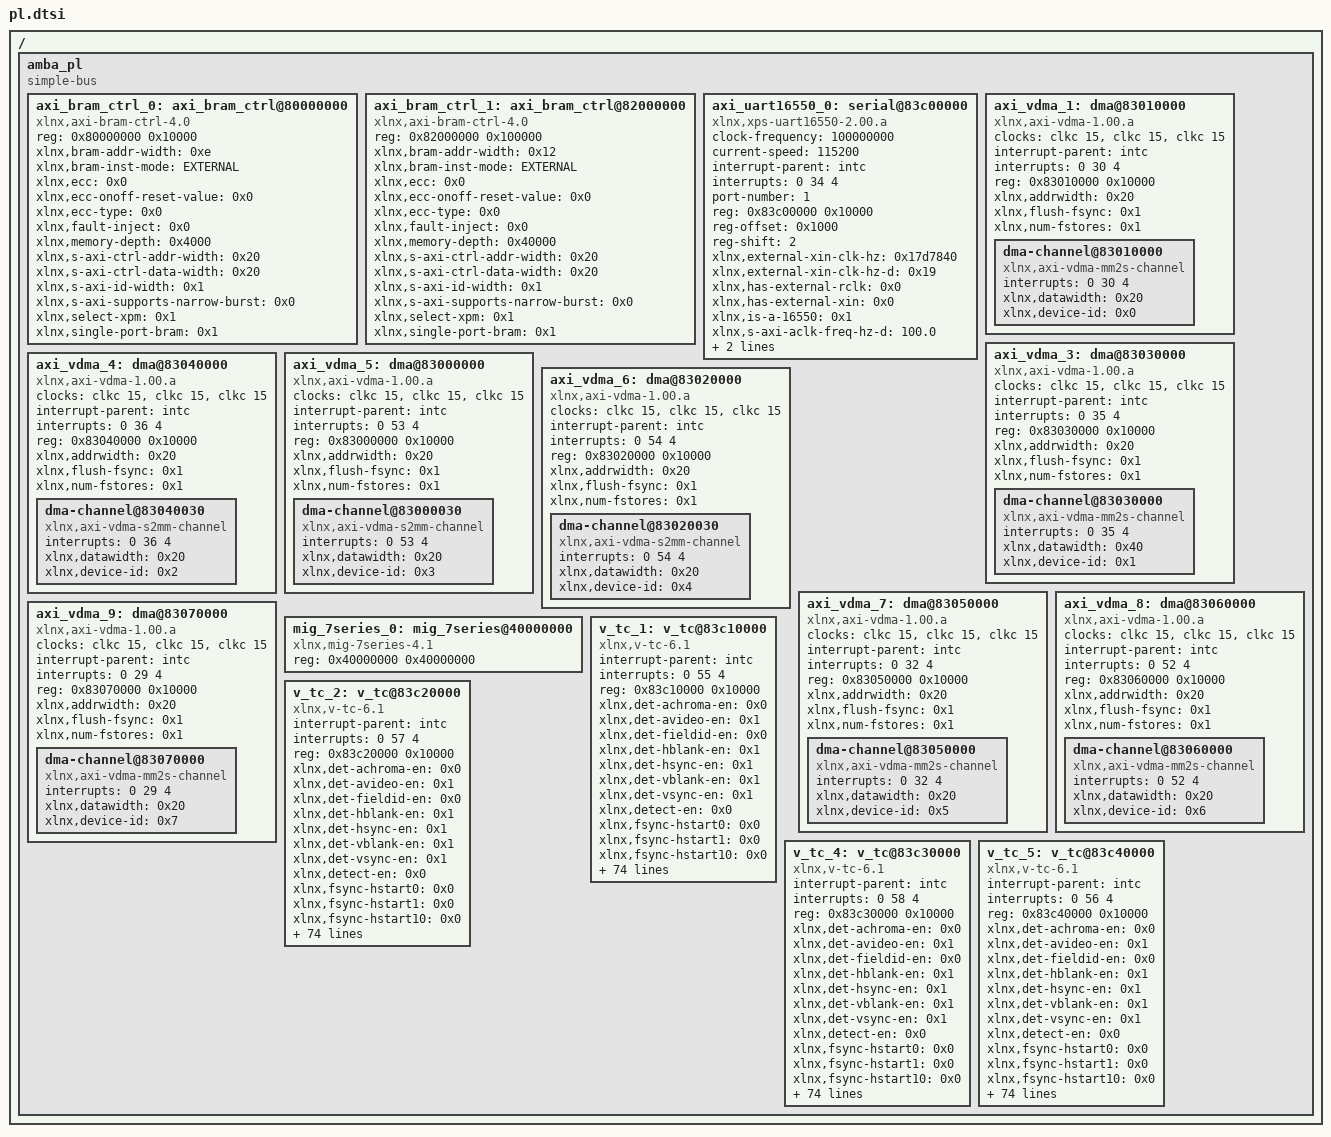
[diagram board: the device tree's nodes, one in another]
/*
 * CAUTION: This file is automatically generated by Xilinx.
 * Version:  
 * Today is: Fri Aug 23 22:00:20 2019
 */


/ {
	amba_pl: amba_pl {
		#address-cells = <1>;
		#size-cells = <1>;
		compatible = "simple-bus";
		ranges ;
		axi_bram_ctrl_0: axi_bram_ctrl@80000000 {
			compatible = "xlnx,axi-bram-ctrl-4.0";
			reg = <0x80000000 0x10000>;
			xlnx,bram-addr-width = <0xe>;
			xlnx,bram-inst-mode = "EXTERNAL";
			xlnx,ecc = <0x0>;
			xlnx,ecc-onoff-reset-value = <0x0>;
			xlnx,ecc-type = <0x0>;
			xlnx,fault-inject = <0x0>;
			xlnx,memory-depth = <0x4000>;
			xlnx,s-axi-ctrl-addr-width = <0x20>;
			xlnx,s-axi-ctrl-data-width = <0x20>;
			xlnx,s-axi-id-width = <0x1>;
			xlnx,s-axi-supports-narrow-burst = <0x0>;
			xlnx,select-xpm = <0x1>;
			xlnx,single-port-bram = <0x1>;
		};
		axi_bram_ctrl_1: axi_bram_ctrl@82000000 {
			compatible = "xlnx,axi-bram-ctrl-4.0";
			reg = <0x82000000 0x100000>;
			xlnx,bram-addr-width = <0x12>;
			xlnx,bram-inst-mode = "EXTERNAL";
			xlnx,ecc = <0x0>;
			xlnx,ecc-onoff-reset-value = <0x0>;
			xlnx,ecc-type = <0x0>;
			xlnx,fault-inject = <0x0>;
			xlnx,memory-depth = <0x40000>;
			xlnx,s-axi-ctrl-addr-width = <0x20>;
			xlnx,s-axi-ctrl-data-width = <0x20>;
			xlnx,s-axi-id-width = <0x1>;
			xlnx,s-axi-supports-narrow-burst = <0x0>;
			xlnx,select-xpm = <0x1>;
			xlnx,single-port-bram = <0x1>;
		};
		axi_uart16550_0: serial@83c00000 {
			clock-frequency = <100000000>;
			clock-names = "s_axi_aclk";
			compatible = "xlnx,xps-uart16550-2.00.a", "ns16550a";
			current-speed = <115200>;
			device_type = "serial";
			interrupt-names = "ip2intc_irpt";
			interrupt-parent = <&intc>;
			interrupts = <0 34 4>;
			port-number = <1>;
			reg = <0x83c00000 0x10000>;
			reg-offset = <0x1000>;
			reg-shift = <2>;
			xlnx,external-xin-clk-hz = <0x17d7840>;
			xlnx,external-xin-clk-hz-d = <0x19>;
			xlnx,has-external-rclk = <0x0>;
			xlnx,has-external-xin = <0x0>;
			xlnx,is-a-16550 = <0x1>;
			xlnx,s-axi-aclk-freq-hz-d = "100.0";
			xlnx,use-modem-ports = <0x1>;
			xlnx,use-user-ports = <0x1>;
		};
		axi_vdma_1: dma@83010000 {
			#dma-cells = <1>;
			clock-names = "s_axi_lite_aclk", "m_axi_mm2s_aclk", "m_axi_mm2s_aclk";
			clocks = <&clkc 15>, <&clkc 15>, <&clkc 15>;
			compatible = "xlnx,axi-vdma-1.00.a";
			interrupt-names = "mm2s_introut";
			interrupt-parent = <&intc>;
			interrupts = <0 30 4>;
			reg = <0x83010000 0x10000>;
			xlnx,addrwidth = <0x20>;
			xlnx,flush-fsync = <0x1>;
			xlnx,num-fstores = <0x1>;
			dma-channel@83010000 {
				compatible = "xlnx,axi-vdma-mm2s-channel";
				interrupts = <0 30 4>;
				xlnx,datawidth = <0x20>;
				xlnx,device-id = <0x0>;
			};
		};
		axi_vdma_3: dma@83030000 {
			#dma-cells = <1>;
			clock-names = "s_axi_lite_aclk", "m_axi_mm2s_aclk", "m_axi_mm2s_aclk";
			clocks = <&clkc 15>, <&clkc 15>, <&clkc 15>;
			compatible = "xlnx,axi-vdma-1.00.a";
			interrupt-names = "mm2s_introut";
			interrupt-parent = <&intc>;
			interrupts = <0 35 4>;
			reg = <0x83030000 0x10000>;
			xlnx,addrwidth = <0x20>;
			xlnx,flush-fsync = <0x1>;
			xlnx,num-fstores = <0x1>;
			dma-channel@83030000 {
				compatible = "xlnx,axi-vdma-mm2s-channel";
				interrupts = <0 35 4>;
				xlnx,datawidth = <0x40>;
				xlnx,device-id = <0x1>;
			};
		};
		axi_vdma_4: dma@83040000 {
			#dma-cells = <1>;
			clock-names = "s_axi_lite_aclk", "m_axi_s2mm_aclk", "m_axi_s2mm_aclk";
			clocks = <&clkc 15>, <&clkc 15>, <&clkc 15>;
			compatible = "xlnx,axi-vdma-1.00.a";
			interrupt-names = "s2mm_introut";
			interrupt-parent = <&intc>;
			interrupts = <0 36 4>;
			reg = <0x83040000 0x10000>;
			xlnx,addrwidth = <0x20>;
			xlnx,flush-fsync = <0x1>;
			xlnx,num-fstores = <0x1>;
			dma-channel@83040030 {
				compatible = "xlnx,axi-vdma-s2mm-channel";
				interrupts = <0 36 4>;
				xlnx,datawidth = <0x20>;
				xlnx,device-id = <0x2>;
			};
		};
		axi_vdma_5: dma@83000000 {
			#dma-cells = <1>;
			clock-names = "s_axi_lite_aclk", "m_axi_s2mm_aclk", "m_axi_s2mm_aclk";
			clocks = <&clkc 15>, <&clkc 15>, <&clkc 15>;
			compatible = "xlnx,axi-vdma-1.00.a";
			interrupt-names = "s2mm_introut";
			interrupt-parent = <&intc>;
			interrupts = <0 53 4>;
			reg = <0x83000000 0x10000>;
			xlnx,addrwidth = <0x20>;
			xlnx,flush-fsync = <0x1>;
			xlnx,num-fstores = <0x1>;
			dma-channel@83000030 {
				compatible = "xlnx,axi-vdma-s2mm-channel";
				interrupts = <0 53 4>;
				xlnx,datawidth = <0x20>;
				xlnx,device-id = <0x3>;
			};
		};
		axi_vdma_6: dma@83020000 {
			#dma-cells = <1>;
			clock-names = "s_axi_lite_aclk", "m_axi_s2mm_aclk", "m_axi_s2mm_aclk";
			clocks = <&clkc 15>, <&clkc 15>, <&clkc 15>;
			compatible = "xlnx,axi-vdma-1.00.a";
			interrupt-names = "s2mm_introut";
			interrupt-parent = <&intc>;
			interrupts = <0 54 4>;
			reg = <0x83020000 0x10000>;
			xlnx,addrwidth = <0x20>;
			xlnx,flush-fsync = <0x1>;
			xlnx,num-fstores = <0x1>;
			dma-channel@83020030 {
				compatible = "xlnx,axi-vdma-s2mm-channel";
				interrupts = <0 54 4>;
				xlnx,datawidth = <0x20>;
				xlnx,device-id = <0x4>;
			};
		};
		axi_vdma_7: dma@83050000 {
			#dma-cells = <1>;
			clock-names = "s_axi_lite_aclk", "m_axi_mm2s_aclk", "m_axi_mm2s_aclk";
			clocks = <&clkc 15>, <&clkc 15>, <&clkc 15>;
			compatible = "xlnx,axi-vdma-1.00.a";
			interrupt-names = "mm2s_introut";
			interrupt-parent = <&intc>;
			interrupts = <0 32 4>;
			reg = <0x83050000 0x10000>;
			xlnx,addrwidth = <0x20>;
			xlnx,flush-fsync = <0x1>;
			xlnx,num-fstores = <0x1>;
			dma-channel@83050000 {
				compatible = "xlnx,axi-vdma-mm2s-channel";
				interrupts = <0 32 4>;
				xlnx,datawidth = <0x20>;
				xlnx,device-id = <0x5>;
			};
		};
		axi_vdma_8: dma@83060000 {
			#dma-cells = <1>;
			clock-names = "s_axi_lite_aclk", "m_axi_mm2s_aclk", "m_axi_mm2s_aclk";
			clocks = <&clkc 15>, <&clkc 15>, <&clkc 15>;
			compatible = "xlnx,axi-vdma-1.00.a";
			interrupt-names = "mm2s_introut";
			interrupt-parent = <&intc>;
			interrupts = <0 52 4>;
			reg = <0x83060000 0x10000>;
			xlnx,addrwidth = <0x20>;
			xlnx,flush-fsync = <0x1>;
			xlnx,num-fstores = <0x1>;
			dma-channel@83060000 {
				compatible = "xlnx,axi-vdma-mm2s-channel";
				interrupts = <0 52 4>;
				xlnx,datawidth = <0x20>;
				xlnx,device-id = <0x6>;
			};
		};
		axi_vdma_9: dma@83070000 {
			#dma-cells = <1>;
			clock-names = "s_axi_lite_aclk", "m_axi_mm2s_aclk", "m_axi_mm2s_aclk";
			clocks = <&clkc 15>, <&clkc 15>, <&clkc 15>;
			compatible = "xlnx,axi-vdma-1.00.a";
			interrupt-names = "mm2s_introut";
			interrupt-parent = <&intc>;
			interrupts = <0 29 4>;
			reg = <0x83070000 0x10000>;
			xlnx,addrwidth = <0x20>;
			xlnx,flush-fsync = <0x1>;
			xlnx,num-fstores = <0x1>;
			dma-channel@83070000 {
				compatible = "xlnx,axi-vdma-mm2s-channel";
				interrupts = <0 29 4>;
				xlnx,datawidth = <0x20>;
				xlnx,device-id = <0x7>;
			};
		};
		mig_7series_0: mig_7series@40000000 {
			compatible = "xlnx,mig-7series-4.1";
			reg = <0x40000000 0x40000000>;
		};
		v_tc_1: v_tc@83c10000 {
			compatible = "xlnx,v-tc-6.1";
			interrupt-names = "irq";
			interrupt-parent = <&intc>;
			interrupts = <0 55 4>;
			reg = <0x83c10000 0x10000>;
			xlnx,det-achroma-en = <0x0>;
			xlnx,det-avideo-en = <0x1>;
			xlnx,det-fieldid-en = <0x0>;
			xlnx,det-hblank-en = <0x1>;
			xlnx,det-hsync-en = <0x1>;
			xlnx,det-vblank-en = <0x1>;
			xlnx,det-vsync-en = <0x1>;
			xlnx,detect-en = <0x0>;
			xlnx,fsync-hstart0 = <0x0>;
			xlnx,fsync-hstart1 = <0x0>;
			xlnx,fsync-hstart10 = <0x0>;
			xlnx,fsync-hstart11 = <0x0>;
			xlnx,fsync-hstart12 = <0x0>;
			xlnx,fsync-hstart13 = <0x0>;
			xlnx,fsync-hstart14 = <0x0>;
			xlnx,fsync-hstart15 = <0x0>;
			xlnx,fsync-hstart2 = <0x0>;
			xlnx,fsync-hstart3 = <0x0>;
			xlnx,fsync-hstart4 = <0x0>;
			xlnx,fsync-hstart5 = <0x0>;
			xlnx,fsync-hstart6 = <0x0>;
			xlnx,fsync-hstart7 = <0x0>;
			xlnx,fsync-hstart8 = <0x0>;
			xlnx,fsync-hstart9 = <0x0>;
			xlnx,fsync-vstart0 = <0x0>;
			xlnx,fsync-vstart1 = <0x0>;
			xlnx,fsync-vstart10 = <0x0>;
			xlnx,fsync-vstart11 = <0x0>;
			xlnx,fsync-vstart12 = <0x0>;
			xlnx,fsync-vstart13 = <0x0>;
			xlnx,fsync-vstart14 = <0x0>;
			xlnx,fsync-vstart15 = <0x0>;
			xlnx,fsync-vstart2 = <0x0>;
			xlnx,fsync-vstart3 = <0x0>;
			xlnx,fsync-vstart4 = <0x0>;
			xlnx,fsync-vstart5 = <0x0>;
			xlnx,fsync-vstart6 = <0x0>;
			xlnx,fsync-vstart7 = <0x0>;
			xlnx,fsync-vstart8 = <0x0>;
			xlnx,fsync-vstart9 = <0x0>;
			xlnx,gen-achroma-en = <0x0>;
			xlnx,gen-achroma-polarity = <0x1>;
			xlnx,gen-auto-switch = <0x0>;
			xlnx,gen-avideo-en = <0x1>;
			xlnx,gen-avideo-polarity = <0x1>;
			xlnx,gen-cparity = <0x0>;
			xlnx,gen-f0-vblank-hend = <0x280>;
			xlnx,gen-f0-vblank-hstart = <0x280>;
			xlnx,gen-f0-vframe-size = <0x429>;
			xlnx,gen-f0-vsync-hend = <0x280>;
			xlnx,gen-f0-vsync-hstart = <0x280>;
			xlnx,gen-f0-vsync-vend = <0x41e>;
			xlnx,gen-f0-vsync-vstart = <0x41a>;
			xlnx,gen-f1-vblank-hend = <0x780>;
			xlnx,gen-f1-vblank-hstart = <0x780>;
			xlnx,gen-f1-vframe-size = <0x465>;
			xlnx,gen-f1-vsync-hend = <0x780>;
			xlnx,gen-f1-vsync-hstart = <0x780>;
			xlnx,gen-f1-vsync-vend = <0x440>;
			xlnx,gen-f1-vsync-vstart = <0x43b>;
			xlnx,gen-fieldid-en = <0x0>;
			xlnx,gen-fieldid-polarity = <0x1>;
			xlnx,gen-hactive-size = <0x280>;
			xlnx,gen-hblank-en = <0x1>;
			xlnx,gen-hblank-polarity = <0x1>;
			xlnx,gen-hframe-size = <0x48a>;
			xlnx,gen-hsync-en = <0x1>;
			xlnx,gen-hsync-end = <0x402>;
			xlnx,gen-hsync-polarity = <0x1>;
			xlnx,gen-hsync-start = <0x3ec>;
			xlnx,gen-interlaced = <0x0>;
			xlnx,gen-vactive-size = <0x400>;
			xlnx,gen-vblank-en = <0x1>;
			xlnx,gen-vblank-polarity = <0x1>;
			xlnx,gen-video-format = <0x2>;
			xlnx,gen-vsync-en = <0x1>;
			xlnx,gen-vsync-polarity = <0x1>;
			xlnx,generate-en = <0x1>;
			xlnx,has-axi4-lite = <0x1>;
			xlnx,has-intc-if = <0x0>;
			xlnx,interlace-en = <0x0>;
			xlnx,max-lines = <0x1000>;
			xlnx,max-pixels = <0x1000>;
			xlnx,num-fsyncs = <0x1>;
			xlnx,sync-en = <0x0>;
		};
		v_tc_2: v_tc@83c20000 {
			compatible = "xlnx,v-tc-6.1";
			interrupt-names = "irq";
			interrupt-parent = <&intc>;
			interrupts = <0 57 4>;
			reg = <0x83c20000 0x10000>;
			xlnx,det-achroma-en = <0x0>;
			xlnx,det-avideo-en = <0x1>;
			xlnx,det-fieldid-en = <0x0>;
			xlnx,det-hblank-en = <0x1>;
			xlnx,det-hsync-en = <0x1>;
			xlnx,det-vblank-en = <0x1>;
			xlnx,det-vsync-en = <0x1>;
			xlnx,detect-en = <0x0>;
			xlnx,fsync-hstart0 = <0x0>;
			xlnx,fsync-hstart1 = <0x0>;
			xlnx,fsync-hstart10 = <0x0>;
			xlnx,fsync-hstart11 = <0x0>;
			xlnx,fsync-hstart12 = <0x0>;
			xlnx,fsync-hstart13 = <0x0>;
			xlnx,fsync-hstart14 = <0x0>;
			xlnx,fsync-hstart15 = <0x0>;
			xlnx,fsync-hstart2 = <0x0>;
			xlnx,fsync-hstart3 = <0x0>;
			xlnx,fsync-hstart4 = <0x0>;
			xlnx,fsync-hstart5 = <0x0>;
			xlnx,fsync-hstart6 = <0x0>;
			xlnx,fsync-hstart7 = <0x0>;
			xlnx,fsync-hstart8 = <0x0>;
			xlnx,fsync-hstart9 = <0x0>;
			xlnx,fsync-vstart0 = <0x0>;
			xlnx,fsync-vstart1 = <0x0>;
			xlnx,fsync-vstart10 = <0x0>;
			xlnx,fsync-vstart11 = <0x0>;
			xlnx,fsync-vstart12 = <0x0>;
			xlnx,fsync-vstart13 = <0x0>;
			xlnx,fsync-vstart14 = <0x0>;
			xlnx,fsync-vstart15 = <0x0>;
			xlnx,fsync-vstart2 = <0x0>;
			xlnx,fsync-vstart3 = <0x0>;
			xlnx,fsync-vstart4 = <0x0>;
			xlnx,fsync-vstart5 = <0x0>;
			xlnx,fsync-vstart6 = <0x0>;
			xlnx,fsync-vstart7 = <0x0>;
			xlnx,fsync-vstart8 = <0x0>;
			xlnx,fsync-vstart9 = <0x0>;
			xlnx,gen-achroma-en = <0x0>;
			xlnx,gen-achroma-polarity = <0x1>;
			xlnx,gen-auto-switch = <0x0>;
			xlnx,gen-avideo-en = <0x1>;
			xlnx,gen-avideo-polarity = <0x1>;
			xlnx,gen-cparity = <0x0>;
			xlnx,gen-f0-vblank-hend = <0x3c0>;
			xlnx,gen-f0-vblank-hstart = <0x3c0>;
			xlnx,gen-f0-vframe-size = <0x465>;
			xlnx,gen-f0-vsync-hend = <0x3c0>;
			xlnx,gen-f0-vsync-hstart = <0x3c0>;
			xlnx,gen-f0-vsync-vend = <0x440>;
			xlnx,gen-f0-vsync-vstart = <0x43b>;
			xlnx,gen-f1-vblank-hend = <0x780>;
			xlnx,gen-f1-vblank-hstart = <0x780>;
			xlnx,gen-f1-vframe-size = <0x465>;
			xlnx,gen-f1-vsync-hend = <0x780>;
			xlnx,gen-f1-vsync-hstart = <0x780>;
			xlnx,gen-f1-vsync-vend = <0x440>;
			xlnx,gen-f1-vsync-vstart = <0x43b>;
			xlnx,gen-fieldid-en = <0x0>;
			xlnx,gen-fieldid-polarity = <0x1>;
			xlnx,gen-hactive-size = <0x3c0>;
			xlnx,gen-hblank-en = <0x1>;
			xlnx,gen-hblank-polarity = <0x1>;
			xlnx,gen-hframe-size = <0x44c>;
			xlnx,gen-hsync-en = <0x1>;
			xlnx,gen-hsync-end = <0x402>;
			xlnx,gen-hsync-polarity = <0x1>;
			xlnx,gen-hsync-start = <0x3ec>;
			xlnx,gen-interlaced = <0x0>;
			xlnx,gen-vactive-size = <0x438>;
			xlnx,gen-vblank-en = <0x1>;
			xlnx,gen-vblank-polarity = <0x1>;
			xlnx,gen-video-format = <0x2>;
			xlnx,gen-vsync-en = <0x1>;
			xlnx,gen-vsync-polarity = <0x1>;
			xlnx,generate-en = <0x1>;
			xlnx,has-axi4-lite = <0x1>;
			xlnx,has-intc-if = <0x0>;
			xlnx,interlace-en = <0x0>;
			xlnx,max-lines = <0x1000>;
			xlnx,max-pixels = <0x1000>;
			xlnx,num-fsyncs = <0x1>;
			xlnx,sync-en = <0x0>;
		};
		v_tc_4: v_tc@83c30000 {
			compatible = "xlnx,v-tc-6.1";
			interrupt-names = "irq";
			interrupt-parent = <&intc>;
			interrupts = <0 58 4>;
			reg = <0x83c30000 0x10000>;
			xlnx,det-achroma-en = <0x0>;
			xlnx,det-avideo-en = <0x1>;
			xlnx,det-fieldid-en = <0x0>;
			xlnx,det-hblank-en = <0x1>;
			xlnx,det-hsync-en = <0x1>;
			xlnx,det-vblank-en = <0x1>;
			xlnx,det-vsync-en = <0x1>;
			xlnx,detect-en = <0x0>;
			xlnx,fsync-hstart0 = <0x0>;
			xlnx,fsync-hstart1 = <0x0>;
			xlnx,fsync-hstart10 = <0x0>;
			xlnx,fsync-hstart11 = <0x0>;
			xlnx,fsync-hstart12 = <0x0>;
			xlnx,fsync-hstart13 = <0x0>;
			xlnx,fsync-hstart14 = <0x0>;
			xlnx,fsync-hstart15 = <0x0>;
			xlnx,fsync-hstart2 = <0x0>;
			xlnx,fsync-hstart3 = <0x0>;
			xlnx,fsync-hstart4 = <0x0>;
			xlnx,fsync-hstart5 = <0x0>;
			xlnx,fsync-hstart6 = <0x0>;
			xlnx,fsync-hstart7 = <0x0>;
			xlnx,fsync-hstart8 = <0x0>;
			xlnx,fsync-hstart9 = <0x0>;
			xlnx,fsync-vstart0 = <0x0>;
			xlnx,fsync-vstart1 = <0x0>;
			xlnx,fsync-vstart10 = <0x0>;
			xlnx,fsync-vstart11 = <0x0>;
			xlnx,fsync-vstart12 = <0x0>;
			xlnx,fsync-vstart13 = <0x0>;
			xlnx,fsync-vstart14 = <0x0>;
			xlnx,fsync-vstart15 = <0x0>;
			xlnx,fsync-vstart2 = <0x0>;
			xlnx,fsync-vstart3 = <0x0>;
			xlnx,fsync-vstart4 = <0x0>;
			xlnx,fsync-vstart5 = <0x0>;
			xlnx,fsync-vstart6 = <0x0>;
			xlnx,fsync-vstart7 = <0x0>;
			xlnx,fsync-vstart8 = <0x0>;
			xlnx,fsync-vstart9 = <0x0>;
			xlnx,gen-achroma-en = <0x0>;
			xlnx,gen-achroma-polarity = <0x1>;
			xlnx,gen-auto-switch = <0x0>;
			xlnx,gen-avideo-en = <0x1>;
			xlnx,gen-avideo-polarity = <0x1>;
			xlnx,gen-cparity = <0x0>;
			xlnx,gen-f0-vblank-hend = <0x168>;
			xlnx,gen-f0-vblank-hstart = <0x168>;
			xlnx,gen-f0-vframe-size = <0x20d>;
			xlnx,gen-f0-vsync-hend = <0x168>;
			xlnx,gen-f0-vsync-hstart = <0x168>;
			xlnx,gen-f0-vsync-vend = <0x1ee>;
			xlnx,gen-f0-vsync-vstart = <0x1e8>;
			xlnx,gen-f1-vblank-hend = <0x2d0>;
			xlnx,gen-f1-vblank-hstart = <0x2d0>;
			xlnx,gen-f1-vframe-size = <0x20d>;
			xlnx,gen-f1-vsync-hend = <0x2d0>;
			xlnx,gen-f1-vsync-hstart = <0x2d0>;
			xlnx,gen-f1-vsync-vend = <0x1ee>;
			xlnx,gen-f1-vsync-vstart = <0x1e8>;
			xlnx,gen-fieldid-en = <0x0>;
			xlnx,gen-fieldid-polarity = <0x1>;
			xlnx,gen-hactive-size = <0x168>;
			xlnx,gen-hblank-en = <0x1>;
			xlnx,gen-hblank-polarity = <0x1>;
			xlnx,gen-hframe-size = <0x1ad>;
			xlnx,gen-hsync-en = <0x1>;
			xlnx,gen-hsync-end = <0x18f>;
			xlnx,gen-hsync-polarity = <0x1>;
			xlnx,gen-hsync-start = <0x170>;
			xlnx,gen-interlaced = <0x0>;
			xlnx,gen-vactive-size = <0x1e0>;
			xlnx,gen-vblank-en = <0x1>;
			xlnx,gen-vblank-polarity = <0x1>;
			xlnx,gen-video-format = <0x2>;
			xlnx,gen-vsync-en = <0x1>;
			xlnx,gen-vsync-polarity = <0x1>;
			xlnx,generate-en = <0x1>;
			xlnx,has-axi4-lite = <0x1>;
			xlnx,has-intc-if = <0x0>;
			xlnx,interlace-en = <0x0>;
			xlnx,max-lines = <0x1000>;
			xlnx,max-pixels = <0x1000>;
			xlnx,num-fsyncs = <0x1>;
			xlnx,sync-en = <0x0>;
		};
		v_tc_5: v_tc@83c40000 {
			compatible = "xlnx,v-tc-6.1";
			interrupt-names = "irq";
			interrupt-parent = <&intc>;
			interrupts = <0 56 4>;
			reg = <0x83c40000 0x10000>;
			xlnx,det-achroma-en = <0x0>;
			xlnx,det-avideo-en = <0x1>;
			xlnx,det-fieldid-en = <0x0>;
			xlnx,det-hblank-en = <0x1>;
			xlnx,det-hsync-en = <0x1>;
			xlnx,det-vblank-en = <0x1>;
			xlnx,det-vsync-en = <0x1>;
			xlnx,detect-en = <0x0>;
			xlnx,fsync-hstart0 = <0x0>;
			xlnx,fsync-hstart1 = <0x0>;
			xlnx,fsync-hstart10 = <0x0>;
			xlnx,fsync-hstart11 = <0x0>;
			xlnx,fsync-hstart12 = <0x0>;
			xlnx,fsync-hstart13 = <0x0>;
			xlnx,fsync-hstart14 = <0x0>;
			xlnx,fsync-hstart15 = <0x0>;
			xlnx,fsync-hstart2 = <0x0>;
			xlnx,fsync-hstart3 = <0x0>;
			xlnx,fsync-hstart4 = <0x0>;
			xlnx,fsync-hstart5 = <0x0>;
			xlnx,fsync-hstart6 = <0x0>;
			xlnx,fsync-hstart7 = <0x0>;
			xlnx,fsync-hstart8 = <0x0>;
			xlnx,fsync-hstart9 = <0x0>;
			xlnx,fsync-vstart0 = <0x0>;
			xlnx,fsync-vstart1 = <0x0>;
			xlnx,fsync-vstart10 = <0x0>;
			xlnx,fsync-vstart11 = <0x0>;
			xlnx,fsync-vstart12 = <0x0>;
			xlnx,fsync-vstart13 = <0x0>;
			xlnx,fsync-vstart14 = <0x0>;
			xlnx,fsync-vstart15 = <0x0>;
			xlnx,fsync-vstart2 = <0x0>;
			xlnx,fsync-vstart3 = <0x0>;
			xlnx,fsync-vstart4 = <0x0>;
			xlnx,fsync-vstart5 = <0x0>;
			xlnx,fsync-vstart6 = <0x0>;
			xlnx,fsync-vstart7 = <0x0>;
			xlnx,fsync-vstart8 = <0x0>;
			xlnx,fsync-vstart9 = <0x0>;
			xlnx,gen-achroma-en = <0x0>;
			xlnx,gen-achroma-polarity = <0x1>;
			xlnx,gen-auto-switch = <0x0>;
			xlnx,gen-avideo-en = <0x1>;
			xlnx,gen-avideo-polarity = <0x1>;
			xlnx,gen-cparity = <0x0>;
			xlnx,gen-f0-vblank-hend = <0x3c0>;
			xlnx,gen-f0-vblank-hstart = <0x3c0>;
			xlnx,gen-f0-vframe-size = <0x465>;
			xlnx,gen-f0-vsync-hend = <0x3c0>;
			xlnx,gen-f0-vsync-hstart = <0x3c0>;
			xlnx,gen-f0-vsync-vend = <0x440>;
			xlnx,gen-f0-vsync-vstart = <0x43b>;
			xlnx,gen-f1-vblank-hend = <0x780>;
			xlnx,gen-f1-vblank-hstart = <0x780>;
			xlnx,gen-f1-vframe-size = <0x465>;
			xlnx,gen-f1-vsync-hend = <0x780>;
			xlnx,gen-f1-vsync-hstart = <0x780>;
			xlnx,gen-f1-vsync-vend = <0x440>;
			xlnx,gen-f1-vsync-vstart = <0x43b>;
			xlnx,gen-fieldid-en = <0x0>;
			xlnx,gen-fieldid-polarity = <0x1>;
			xlnx,gen-hactive-size = <0x3c0>;
			xlnx,gen-hblank-en = <0x1>;
			xlnx,gen-hblank-polarity = <0x1>;
			xlnx,gen-hframe-size = <0x44c>;
			xlnx,gen-hsync-en = <0x1>;
			xlnx,gen-hsync-end = <0x402>;
			xlnx,gen-hsync-polarity = <0x1>;
			xlnx,gen-hsync-start = <0x3ec>;
			xlnx,gen-interlaced = <0x0>;
			xlnx,gen-vactive-size = <0x438>;
			xlnx,gen-vblank-en = <0x1>;
			xlnx,gen-vblank-polarity = <0x1>;
			xlnx,gen-video-format = <0x2>;
			xlnx,gen-vsync-en = <0x1>;
			xlnx,gen-vsync-polarity = <0x1>;
			xlnx,generate-en = <0x1>;
			xlnx,has-axi4-lite = <0x1>;
			xlnx,has-intc-if = <0x0>;
			xlnx,interlace-en = <0x0>;
			xlnx,max-lines = <0x1000>;
			xlnx,max-pixels = <0x1000>;
			xlnx,num-fsyncs = <0x1>;
			xlnx,sync-en = <0x0>;
		};
	};
};
